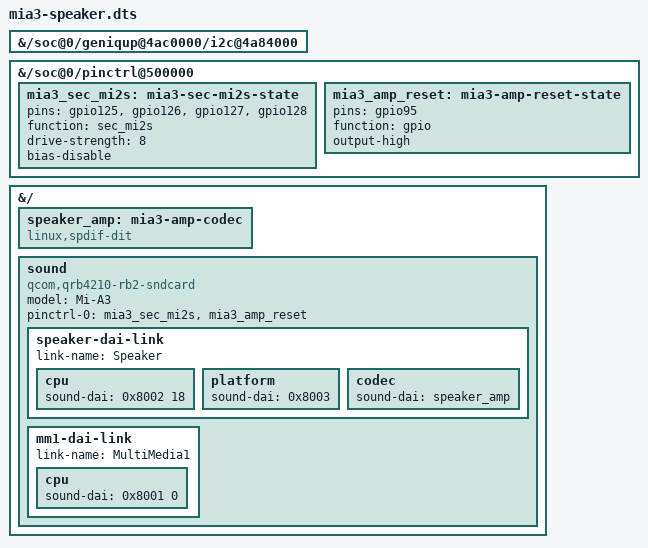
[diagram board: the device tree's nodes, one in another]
/dts-v1/;
/plugin/;
/* Speaker card: q6asm dais -> q6routing -> SECONDARY_MI2S_RX (gpio125-128) -> MAX98937 amp (1-003a).
 * The amp is a MAX98937, not the MAX98927 the stock DT names: no mainline driver, so the link ends in a
 * dummy codec and max98937-init.sh sets the amp up over i2c-dev.
 * Apply with mia3_dtbo.ko ph=<asm dais>=0x8001,<afe dais>=0x8002,<routing>=0x8003 pdev=/mia3-amp-codec,/sound (bringup.sh).
 * Links speaker-first: overlay children attach in reverse order. */
&{/soc@0/geniqup@4ac0000/i2c@4a84000} {
	status = "okay";
};
&{/soc@0/pinctrl@500000} {
	mia3_sec_mi2s: mia3-sec-mi2s-state {
		pins = "gpio125", "gpio126", "gpio127", "gpio128";
		function = "sec_mi2s";
		drive-strength = <8>;
		bias-disable;
	};
	mia3_amp_reset: mia3-amp-reset-state {
		pins = "gpio95";	/* MAX98937 RESET_N, held high = out of reset */
		function = "gpio";
		output-high;
	};
};
&{/} {
	speaker_amp: mia3-amp-codec {
		compatible = "linux,spdif-dit";
		#sound-dai-cells = <0>;
	};
	sound {
		compatible = "qcom,qrb4210-rb2-sndcard";
		model = "Mi-A3";
		pinctrl-0 = <&mia3_sec_mi2s &mia3_amp_reset>;
		pinctrl-names = "default";
		speaker-dai-link {
			link-name = "Speaker";
			cpu { sound-dai = <0x8002 18>; };
			platform { sound-dai = <0x8003>; };
			codec { sound-dai = <&speaker_amp>; };
		};
		mm1-dai-link {
			link-name = "MultiMedia1";
			cpu { sound-dai = <0x8001 0>; };
		};
	};
};
